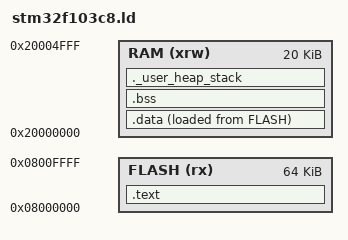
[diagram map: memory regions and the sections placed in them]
/* =====================================================
   STM32F103C8T6 LINKER SCRIPT
   Flash = 64 KB
   RAM   = 20 KB
   ===================================================== */

ENTRY(Reset_Handler)


/* =====================================================
   Memory
   ===================================================== */

MEMORY
{
    FLASH (rx)  : ORIGIN = 0x08000000, LENGTH = 64K
    RAM   (xrw) : ORIGIN = 0x20000000, LENGTH = 20K
}


/* =====================================================
   Stack
   ===================================================== */

_estack = ORIGIN(RAM) + LENGTH(RAM);


/* =====================================================
   Sections
   ===================================================== */

SECTIONS
{

    /* -------------------------------------------------
       Vector table + program code
       ------------------------------------------------- */

    .text :
    {
        . = ALIGN(4);

        KEEP(*(.isr_vector))

        *(.text)
        *(.text*)

        *(.rodata)
        *(.rodata*)

        . = ALIGN(4);

        _etext = .;

    } > FLASH


    /* -------------------------------------------------
       Initialized data
       ------------------------------------------------- */

    _sidata = LOADADDR(.data);

    .data :
    {
        . = ALIGN(4);

        _sdata = .;

        *(.data)
        *(.data*)

        . = ALIGN(4);

        _edata = .;

    } > RAM AT > FLASH


    /* -------------------------------------------------
       Uninitialized data
       ------------------------------------------------- */

    .bss :
    {
        . = ALIGN(4);

        _sbss = .;

        *(.bss)
        *(.bss*)
        *(COMMON)

        . = ALIGN(4);

        _ebss = .;

    } > RAM


    /* -------------------------------------------------
       Stack / heap
       ------------------------------------------------- */

    ._user_heap_stack :
    {
        . = ALIGN(8);

        . = . + 0x400;

        . = . + 0x400;

        . = ALIGN(8);

    } > RAM


    /* -------------------------------------------------
       Remove unnecessary sections
       ------------------------------------------------- */

    /DISCARD/ :
    {
        *(.note*)
        *(.comment*)
    }
}
